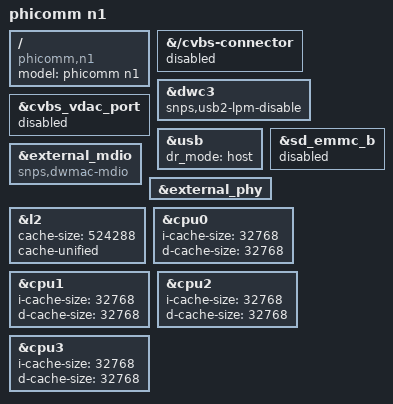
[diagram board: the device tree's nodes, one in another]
// SPDX-License-Identifier: (GPL-2.0+ OR MIT)
/*
* Copyright (c) 2018 He Yangxuan
* Copyright (c) 2022 He Justin
*/

/dts-v1/;

#include "meson-gxl-s905d-p230.dts"

/ {
    compatible = "phicomm,n1", "amlogic,p230", "amlogic,s905d", "amlogic,meson-gxl";
    model = "phicomm n1";

    /*
    leds {
        compatible = "gpio-leds";
        status {
            label = "n1:white:status";
            gpios = <&gpio_ao GPIOAO_9 GPIO_ACTIVE_HIGH>;
            default-state = "on";
        };
    };
    */
};

&{/cvbs-connector} {
    status = "disabled";
};

&dwc3 {
    /* fix usb compatible issue */
    /* https://www.kernel.org/doc/Documentation/devicetree/bindings/usb/generic.txt */
    snps,usb2-lpm-disable;
};

&cvbs_vdac_port {
    status = "disabled";
};

&usb {
    dr_mode = "host";
};

&sd_emmc_b {
    /* n1 does not have sd card, disable it */
    status = "disabled";
};

&external_mdio {
    /* fix: Error: Failed to register MDIO bus for child /soc/bus@c8834000/eth-phy-mux/mdio@2009087f */
    /* fix: high cpu load issue */
    compatible = "snps,dwmac-mdio";
};

&external_phy {
    /* eee-broken-1000t is no longer needed */
    /delete-property/ eee-broken-1000t;
};

&l2 {
    /* 512KB cache size, needed by linux 6.3 */
    cache-size = <524288>;
    cache-unified;
};

&cpu0 {
    /* 32KB L1 cache size */
    i-cache-size = <32768>;
    d-cache-size = <32768>;
};

&cpu1 {
    /* 32KB L1 cache size */
    i-cache-size = <32768>;
    d-cache-size = <32768>;
};

&cpu2 {
    /* 32KB L1 cache size */
    i-cache-size = <32768>;
    d-cache-size = <32768>;
};

&cpu3 {
    /* 32KB L1 cache size */
    i-cache-size = <32768>;
    d-cache-size = <32768>;
};

/* This UART is connected to the Bluetooth module */
/*
&uart_A {
    status = "okay";
    pinctrl-0 = <&uart_a_pins>, <&uart_a_cts_rts_pins>;
    pinctrl-names = "default";
    uart-has-rtscts;

    bluetooth {
        compatible = "brcm,bcm43438-bt";
        shutdown-gpios = <&gpio GPIOX_17 GPIO_ACTIVE_HIGH>;
        max-speed = <2000000>;
        clocks = <&wifi32k>;
        clock-names = "lpo";
    };
};
*/
